# ha_reva register map
Registers are read-only, no defined reset value unless marked. A register's access mark holds for its fields unless they carry their own. Offsets are from the block's base; lines under a group give offsets from that group; [hi:lo] are bit positions; {n}, {i} and the like mark numbered series; 'fields as' and 'values as' point back to an identical list; <NAME> marks a mode.

## Memory map
0x40036000 HA size 0x1000 — Hardware Accelerator

## Interrupts
60 HA — Smart DMA interrupt.

## HA — Hardware Accelerator
Base 0x40036000
0x00 IP — Q30E Instruction Pointer.
0x04 SP — Q30E Stack Pointer.
0x08 DP0 — Q30E Data Pointer 0.
0x0C DP1 — Q30E Data Pointer 1.
0x10 BP — Q30E Frame Pointer Base.
0x14 OFFS — Q30E Frame Pointer Offset.
0x18 LC0 — Q30E Loop Counter 0.
0x1C LC1 — Q30E Loop Counter 1.
{0x20+4i} A{i} (i=0..3) — Q30E Accumulator {i}.
0x30 WDCN — Q30E Watchdog Control.
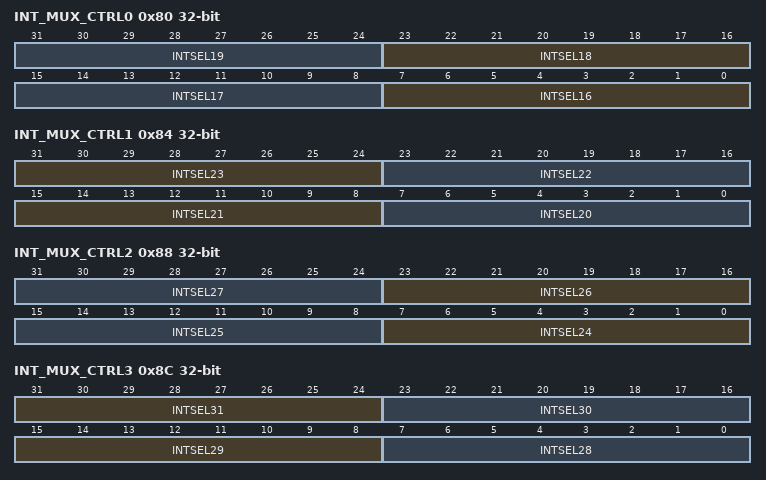
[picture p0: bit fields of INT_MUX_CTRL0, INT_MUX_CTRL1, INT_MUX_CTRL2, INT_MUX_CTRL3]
0x80 INT_MUX_CTRL0 rw — Interrupt Mux Control 0.
  [8n-121:8n-128] INTSEL{n} (n=16..19) — Interrupt Selection For {n}th Interrupt.
0x84 INT_MUX_CTRL1 rw — Interrupt Mux Control 1.
  [31:24] INTSEL23 — Interrupt Selection For 23rd Interrupt.
  [23:16] INTSEL22 — Interrupt Selection For 22nd Interrupt.
  [15:8] INTSEL21 — Interrupt Selection For 21st Interrupt.
  [7:0] INTSEL20 — Interrupt Selection For 20th Interrupt.
0x88 INT_MUX_CTRL2 rw — Interrupt Mux Control 2.
  [8n-185:8n-192] INTSEL{n} (n=24..27) — Interrupt Selection For {n}th Interrupt.
0x8C INT_MUX_CTRL3 rw — Interrupt Mux Control 3.
  [31:24] INTSEL31 — Interrupt Selection For 31st Interrupt.
  [23:16] INTSEL30 — Interrupt Selection For 30th Interrupt.
  [15:8] INTSEL29 — Interrupt Selection For 29th Interrupt.
  [7:0] INTSEL28 — Interrupt Selection For 28th Interrupt.
0x90 IP_ADDR rw — Configurable starting IP address for Q30E.
  [31:0] START_IP_ADDR — Starting IP address for Q30E
0x94 CTRL rw — Control Register.
  [0] EN — Enable SDMA.
    0=dis (Disable SDMA.); 1=en (Enable SDMA.)
0xA0 INT_IN_CTRL rw — Interrupt Input From CPU Control Register.
  [0] INTSET — Set Interrupt Flag.
    0=dis (Set interrupt Flag to 0.); 1=set (Set Interrupt Flag to 1.)
0xA4 INT_IN_FLAG rw — Interrupt Input From CPU Flag.
  [0] INTFLAG — Interrupt Flag.
    0=No Effect; 1=clear (INT_IN_FLAG =0)
0xA8 INT_IN_IE rw — Interrupt Input From CPU Enable.
  [0] INT_IN_EN — Interrupt Enable.
0xB0 IRQ_FLAG rw — Interrupt Output To CPU Flag.
  [0] IRQ_FLAG — Interrupt Flag.
0xB4 IRQ_IE rw — Interrupt Output To CPU Control Register.
  [0] IRQ_EN — Interrupt Enable.
